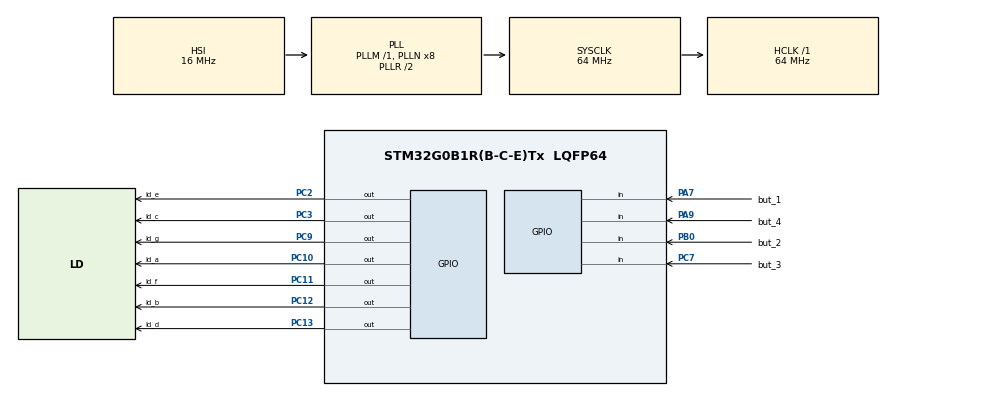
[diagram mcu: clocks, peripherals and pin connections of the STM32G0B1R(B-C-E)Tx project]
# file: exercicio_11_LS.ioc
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Mcu.Family=STM32G0
Mcu.Name=STM32G0B1R(B-C-E)Tx
Mcu.Package=LQFP64
PA13.Mode=Serial_Wire
PA13.Signal=SYS_SWDIO
PA14-BOOT0.Mode=Serial_Wire
PA14-BOOT0.Signal=SYS_SWCLK
PA7.GPIO_Label=but_1
PA7.GPIO_PuPd=GPIO_PULLUP
PA7.Signal=GPIO_Input
PA9.GPIO_Label=but_4
PA9.GPIO_PuPd=GPIO_PULLUP
PA9.Signal=GPIO_Input
PB0.GPIO_Label=but_2
PB0.GPIO_PuPd=GPIO_PULLUP
PB0.Signal=GPIO_Input
PC10.GPIO_Label=ld_a
PC10.PinState=GPIO_PIN_SET
PC10.Signal=GPIO_Output
PC11.GPIO_Label=ld_f
PC11.PinState=GPIO_PIN_SET
PC11.Signal=GPIO_Output
PC12.GPIO_Label=ld_b
PC12.PinState=GPIO_PIN_SET
PC12.Signal=GPIO_Output
PC13.GPIO_Label=ld_d
PC13.PinState=GPIO_PIN_SET
PC13.Signal=GPIO_Output
PC2.GPIO_Label=ld_e
PC2.PinState=GPIO_PIN_SET
PC2.Signal=GPIO_Output
PC3.GPIO_Label=ld_c
PC3.PinState=GPIO_PIN_SET
PC3.Signal=GPIO_Output
PC7.GPIO_Label=but_3
PC7.GPIO_PuPd=GPIO_PULLUP
PC7.Signal=GPIO_Input
PC9.GPIO_Label=ld_g
PC9.PinState=GPIO_PIN_SET
PC9.Signal=GPIO_Output
ProjectManager.HeapSize=0x200
ProjectManager.StackSize=0x400
ProjectManager.TargetToolchain=STM32CubeIDE
RCC.ADCFreq_Value=64000000
RCC.AHBFreq_Value=64000000
RCC.CortexFreq_Value=64000000
RCC.EXTERNAL_CLOCK_VALUE=48000
RCC.HCLKFreq_Value=64000000
RCC.HSE_VALUE=8000000
RCC.HSI48_VALUE=48000000
RCC.HSI_VALUE=16000000
RCC.LSE_VALUE=32768
RCC.SYSCLKFreq_VALUE=64000000
RCC.SYSCLKSource=RCC_SYSCLKSOURCE_PLLCLK
RCC.USBFreq_Value=48000000
RCC.VCOOutputFreq_Value=128000000
VP_SYS_VS_DBSignals.Mode=DisableDeadBatterySignals
board=custom

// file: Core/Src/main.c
/* USER CODE BEGIN Header */
/**
  ******************************************************************************
  * @file           : main.c
  * @brief          : Main program body
  ******************************************************************************
  * @attention
  *
  * Copyright (c) 2022 STMicroelectronics.
  * All rights reserved.
  *
  * This software is licensed under terms that can be found in the LICENSE file
  * in the root directory of this software component.
  * If no LICENSE file comes with this software, it is provided AS-IS.
  *
  ******************************************************************************
  */
/* USER CODE END Header */
#include "main.h"

/* USER CODE BEGIN PV */

uint8_t b1, b2, b3, b4;

uint16_t numero;

/* USER CODE END PV */

void SystemClock_Config(void);
static void MX_GPIO_Init(void);

int main(void)
{

  /* MCU Configuration--------------------------------------------------------*/

  /* Reset of all peripherals, Initializes the Flash interface and the Systick. */
  HAL_Init();

  /* Configure the system clock */
  SystemClock_Config();

  /* Initialize all configured peripherals */
  MX_GPIO_Init();

  /* Infinite loop */
  /* USER CODE BEGIN WHILE */

  numero = 12;
  while (1)
  {
	  b1 = HAL_GPIO_ReadPin(but_1_GPIO_Port, but_1_Pin);
	  b2 = HAL_GPIO_ReadPin(but_2_GPIO_Port, but_2_Pin);
	  b3 = HAL_GPIO_ReadPin(but_3_GPIO_Port, but_3_Pin);
	  b4 = HAL_GPIO_ReadPin(but_4_GPIO_Port, but_4_Pin);

	  numero = b4 + b3*2 + b2*4 + b1*8;

/*	  switch (numero){

  	  case 0:
  		  HAL_GPIO_WritePin(ld_a_GPIO_Port, ld_a_Pin, 0);
  		  HAL_GPIO_WritePin(ld_b_GPIO_Port, ld_b_Pin, 0);
  		  HAL_GPIO_WritePin(ld_c_GPIO_Port, ld_c_Pin, 0);
  		  HAL_GPIO_WritePin(ld_d_GPIO_Port, ld_d_Pin, 0);
  		  HAL_GPIO_WritePin(ld_e_GPIO_Port, ld_e_Pin, 0);
  		  HAL_GPIO_WritePin(ld_f_GPIO_Port, ld_f_Pin, 0);
  		  HAL_GPIO_WritePin(ld_g_GPIO_Port, ld_g_Pin, 1);

  		  break;

	  	  case 1:
	  		  HAL_GPIO_WritePin(ld_a_GPIO_Port, ld_a_Pin, 1);
	  		  HAL_GPIO_WritePin(ld_b_GPIO_Port, ld_b_Pin, 0);
	  		  HAL_GPIO_WritePin(ld_c_GPIO_Port, ld_c_Pin, 0);
	  		  HAL_GPIO_WritePin(ld_d_GPIO_Port, ld_d_Pin, 1);
	  		  HAL_GPIO_WritePin(ld_e_GPIO_Port, ld_e_Pin, 1);
	  		  HAL_GPIO_WritePin(ld_f_GPIO_Port, ld_f_Pin, 1);
	  		  HAL_GPIO_WritePin(ld_g_GPIO_Port, ld_g_Pin, 1);

	  		  break;

	  	  case 2:

	  		  HAL_GPIO_WritePin(ld_a_GPIO_Port, ld_a_Pin, 0);
	  		  HAL_GPIO_WritePin(ld_b_GPIO_Port, ld_b_Pin, 0);
	  		  HAL_GPIO_WritePin(ld_c_GPIO_Port, ld_c_Pin, 1);
	  		  HAL_GPIO_WritePin(ld_d_GPIO_Port, ld_d_Pin, 0);
	  		  HAL_GPIO_WritePin(ld_e_GPIO_Port, ld_e_Pin, 0);
	  		  HAL_GPIO_WritePin(ld_f_GPIO_Port, ld_f_Pin, 1);
	  		  HAL_GPIO_WritePin(ld_g_GPIO_Port, ld_g_Pin, 0);

	  		  break;

	  	  case 3:

	  		  HAL_GPIO_WritePin(ld_a_GPIO_Port, ld_a_Pin, 0);
	  		  HAL_GPIO_WritePin(ld_b_GPIO_Port, ld_b_Pin, 0);
	  		  HAL_GPIO_WritePin(ld_c_GPIO_Port, ld_c_Pin, 0);
	  		  HAL_GPIO_WritePin(ld_d_GPIO_Port, ld_d_Pin, 0);
	  		  HAL_GPIO_WritePin(ld_e_GPIO_Port, ld_e_Pin, 1);
	  		  HAL_GPIO_WritePin(ld_f_GPIO_Port, ld_f_Pin, 1);
	  		  HAL_GPIO_WritePin(ld_g_GPIO_Port, ld_g_Pin, 0);

	  		  break;

	  	  case 4:
	  		  HAL_GPIO_WritePin(ld_a_GPIO_Port, ld_a_Pin, 1);
	  		  HAL_GPIO_WritePin(ld_b_GPIO_Port, ld_b_Pin, 0);
	  		  HAL_GPIO_WritePin(ld_c_GPIO_Port, ld_c_Pin, 0);
	  		  HAL_GPIO_WritePin(ld_d_GPIO_Port, ld_d_Pin, 1);
	  		  HAL_GPIO_WritePin(ld_e_GPIO_Port, ld_e_Pin, 1);
	  		  HAL_GPIO_WritePin(ld_g_GPIO_Port, ld_g_Pin, 0);
	  		  HAL_GPIO_WritePin(ld_f_GPIO_Port, ld_f_Pin, 0);

	  		  break;

	  	  case 5:

	  		  HAL_GPIO_WritePin(ld_a_GPIO_Port, ld_a_Pin, 0);
	  		  HAL_GPIO_WritePin(ld_b_GPIO_Port, ld_b_Pin, 1);
	  		  HAL_GPIO_WritePin(ld_c_GPIO_Port, ld_c_Pin, 0);
	  		  HAL_GPIO_WritePin(ld_d_GPIO_Port, ld_d_Pin, 0);
	  		  HAL_GPIO_WritePin(ld_e_GPIO_Port, ld_e_Pin, 1);
	  		  HAL_GPIO_WritePin(ld_f_GPIO_Port, ld_f_Pin, 0);
	  		  HAL_GPIO_WritePin(ld_g_GPIO_Port, ld_g_Pin, 0);

	  		  break;

	  	  case 6:

	  		  HAL_GPIO_WritePin(ld_b_GPIO_Port, ld_b_Pin, 1);
	  		  HAL_GPIO_WritePin(ld_a_GPIO_Port, ld_a_Pin, 0);
	  		  HAL_GPIO_WritePin(ld_f_GPIO_Port, ld_f_Pin, 0);
	  		  HAL_GPIO_WritePin(ld_e_GPIO_Port, ld_e_Pin, 0);
	  		  HAL_GPIO_WritePin(ld_d_GPIO_Port, ld_d_Pin, 0);
	  		  HAL_GPIO_WritePin(ld_g_GPIO_Port, ld_g_Pin, 0);
	  		  HAL_GPIO_WritePin(ld_c_GPIO_Port, ld_c_Pin, 0);

	  		  break;

	  	  case 7:
	  		  HAL_GPIO_WritePin(ld_a_GPIO_Port, ld_a_Pin, 0);
	  		  HAL_GPIO_WritePin(ld_b_GPIO_Port, ld_b_Pin, 0);
	  		  HAL_GPIO_WritePin(ld_c_GPIO_Port, ld_c_Pin, 0);
	  		  HAL_GPIO_WritePin(ld_d_GPIO_Port, ld_d_Pin, 1);
	  		  HAL_GPIO_WritePin(ld_e_GPIO_Port, ld_e_Pin, 1);
	  		  HAL_GPIO_WritePin(ld_f_GPIO_Port, ld_f_Pin, 1);
	  		  HAL_GPIO_WritePin(ld_g_GPIO_Port, ld_g_Pin, 1);

	  		  break;

	  	  case 8:
	  		  HAL_GPIO_WritePin(ld_a_GPIO_Port, ld_a_Pin, 0);
	  		  HAL_GPIO_WritePin(ld_b_GPIO_Port, ld_b_Pin, 0);
	  		  HAL_GPIO_WritePin(ld_c_GPIO_Port, ld_c_Pin, 0);
	  		  HAL_GPIO_WritePin(ld_d_GPIO_Port, ld_d_Pin, 0);
	  		  HAL_GPIO_WritePin(ld_e_GPIO_Port, ld_e_Pin, 0);
	  		  HAL_GPIO_WritePin(ld_f_GPIO_Port, ld_f_Pin, 0);
	  		  HAL_GPIO_WritePin(ld_g_GPIO_Port, ld_g_Pin, 0);

	  		  break;

	  	  case 9:
	  		  HAL_GPIO_WritePin(ld_a_GPIO_Port, ld_a_Pin, 0);
	  		  HAL_GPIO_WritePin(ld_b_GPIO_Port, ld_b_Pin, 0);
	  		  HAL_GPIO_WritePin(ld_c_GPIO_Port, ld_c_Pin, 0);
	  		  HAL_GPIO_WritePin(ld_d_GPIO_Port, ld_d_Pin, 0);
	  		  HAL_GPIO_WritePin(ld_e_GPIO_Port, ld_e_Pin, 1);
	  		  HAL_GPIO_WritePin(ld_f_GPIO_Port, ld_f_Pin, 0);
	  		  HAL_GPIO_WritePin(ld_g_GPIO_Port, ld_g_Pin, 0);

	  		  break;

	  	  case 10:
	  		  HAL_GPIO_WritePin(ld_a_GPIO_Port, ld_a_Pin, 0);
	  		  HAL_GPIO_WritePin(ld_b_GPIO_Port, ld_b_Pin, 0);
	  		  HAL_GPIO_WritePin(ld_c_GPIO_Port, ld_c_Pin, 0);
	  		  HAL_GPIO_WritePin(ld_d_GPIO_Port, ld_d_Pin, 1);
	  		  HAL_GPIO_WritePin(ld_e_GPIO_Port, ld_e_Pin, 0);
	  		  HAL_GPIO_WritePin(ld_f_GPIO_Port, ld_f_Pin, 0);
	  		  HAL_GPIO_WritePin(ld_g_GPIO_Port, ld_g_Pin, 0);

	  		  break;

	  	  case 11:
	  		  HAL_GPIO_WritePin(ld_a_GPIO_Port, ld_a_Pin, 0);
	  		  HAL_GPIO_WritePin(ld_b_GPIO_Port, ld_b_Pin, 0);
	  		  HAL_GPIO_WritePin(ld_c_GPIO_Port, ld_c_Pin, 0);
	  		  HAL_GPIO_WritePin(ld_d_GPIO_Port, ld_d_Pin, 0);
	  		  HAL_GPIO_WritePin(ld_e_GPIO_Port, ld_e_Pin, 0);
	  		  HAL_GPIO_WritePin(ld_f_GPIO_Port, ld_f_Pin, 0);
	  		  HAL_GPIO_WritePin(ld_g_GPIO_Port, ld_g_Pin, 0);

	  		  break;

	  	  case 12:
	  		  HAL_GPIO_WritePin(ld_a_GPIO_Port, ld_a_Pin, 0);
	  		  HAL_GPIO_WritePin(ld_b_GPIO_Port, ld_b_Pin, 1);
	  		  HAL_GPIO_WritePin(ld_c_GPIO_Port, ld_c_Pin, 1);
	  		  HAL_GPIO_WritePin(ld_d_GPIO_Port, ld_d_Pin, 0);
	  		  HAL_GPIO_WritePin(ld_e_GPIO_Port, ld_e_Pin, 0);
	  		  HAL_GPIO_WritePin(ld_f_GPIO_Port, ld_f_Pin, 0);
	  		  HAL_GPIO_WritePin(ld_g_GPIO_Port, ld_g_Pin, 1);

	  		  break;

	  	  case 13:
	  		  HAL_GPIO_WritePin(ld_a_GPIO_Port, ld_a_Pin, 0);
	  		  HAL_GPIO_WritePin(ld_b_GPIO_Port, ld_b_Pin, 0);
	  		  HAL_GPIO_WritePin(ld_c_GPIO_Port, ld_c_Pin, 0);
	  		  HAL_GPIO_WritePin(ld_d_GPIO_Port, ld_d_Pin, 0);
	  		  HAL_GPIO_WritePin(ld_e_GPIO_Port, ld_e_Pin, 0);
	  		  HAL_GPIO_WritePin(ld_f_GPIO_Port, ld_f_Pin, 0);
	  		  HAL_GPIO_WritePin(ld_g_GPIO_Port, ld_g_Pin, 1);

	  		  break;

	  	  case 14:
	  		  HAL_GPIO_WritePin(ld_a_GPIO_Port, ld_a_Pin, 0);
	  		  HAL_GPIO_WritePin(ld_b_GPIO_Port, ld_b_Pin, 1);
	  		  HAL_GPIO_WritePin(ld_c_GPIO_Port, ld_c_Pin, 1);
	  		  HAL_GPIO_WritePin(ld_d_GPIO_Port, ld_d_Pin, 0);
	  		  HAL_GPIO_WritePin(ld_e_GPIO_Port, ld_e_Pin, 0);
	  		  HAL_GPIO_WritePin(ld_f_GPIO_Port, ld_f_Pin, 0);
	  		  HAL_GPIO_WritePin(ld_g_GPIO_Port, ld_g_Pin, 0);

	  		  break;

	  	  case 15:
	  		  HAL_GPIO_WritePin(ld_a_GPIO_Port, ld_a_Pin, 0);
	  		  HAL_GPIO_WritePin(ld_b_GPIO_Port, ld_b_Pin, 1);
	  		  HAL_GPIO_WritePin(ld_c_GPIO_Port, ld_c_Pin, 1);
	  		  HAL_GPIO_WritePin(ld_d_GPIO_Port, ld_d_Pin, 1);
	  		  HAL_GPIO_WritePin(ld_e_GPIO_Port, ld_e_Pin, 0);
	  		  HAL_GPIO_WritePin(ld_f_GPIO_Port, ld_f_Pin, 0);
	  		  HAL_GPIO_WritePin(ld_g_GPIO_Port, ld_g_Pin, 0);

	  		  break;

	  }

	*/

    /* USER CODE END WHILE */

  }
}

void SystemClock_Config(void)
{
  RCC_OscInitTypeDef RCC_OscInitStruct = {0};
  RCC_ClkInitTypeDef RCC_ClkInitStruct = {0};

  /** Configure the main internal regulator output voltage
  */
  HAL_PWREx_ControlVoltageScaling(PWR_REGULATOR_VOLTAGE_SCALE1);
  /** Initializes the RCC Oscillators according to the specified parameters
  * in the RCC_OscInitTypeDef structure.
  */
  RCC_OscInitStruct.OscillatorType = RCC_OSCILLATORTYPE_HSI;
  RCC_OscInitStruct.HSIState = RCC_HSI_ON;
  RCC_OscInitStruct.HSIDiv = RCC_HSI_DIV1;
  RCC_OscInitStruct.HSICalibrationValue = RCC_HSICALIBRATION_DEFAULT;
  RCC_OscInitStruct.PLL.PLLState = RCC_PLL_ON;
  RCC_OscInitStruct.PLL.PLLSource = RCC_PLLSOURCE_HSI;
  RCC_OscInitStruct.PLL.PLLM = RCC_PLLM_DIV1;
  RCC_OscInitStruct.PLL.PLLN = 8;
  RCC_OscInitStruct.PLL.PLLP = RCC_PLLP_DIV2;
  RCC_OscInitStruct.PLL.PLLQ = RCC_PLLQ_DIV2;
  RCC_OscInitStruct.PLL.PLLR = RCC_PLLR_DIV2;
  if (HAL_RCC_OscConfig(&RCC_OscInitStruct) != HAL_OK)
  {
    Error_Handler();
  }
  /** Initializes the CPU, AHB and APB buses clocks
  */
  RCC_ClkInitStruct.ClockType = RCC_CLOCKTYPE_HCLK|RCC_CLOCKTYPE_SYSCLK
                              |RCC_CLOCKTYPE_PCLK1;
  RCC_ClkInitStruct.SYSCLKSource = RCC_SYSCLKSOURCE_PLLCLK;
  RCC_ClkInitStruct.AHBCLKDivider = RCC_SYSCLK_DIV1;
  RCC_ClkInitStruct.APB1CLKDivider = RCC_HCLK_DIV1;

  if (HAL_RCC_ClockConfig(&RCC_ClkInitStruct, FLASH_LATENCY_2) != HAL_OK)
  {
    Error_Handler();
  }
}

static void MX_GPIO_Init(void)
{
  GPIO_InitTypeDef GPIO_InitStruct = {0};

  /* GPIO Ports Clock Enable */
  __HAL_RCC_GPIOC_CLK_ENABLE();
  __HAL_RCC_GPIOA_CLK_ENABLE();
  __HAL_RCC_GPIOB_CLK_ENABLE();

  /*Configure GPIO pin Output Level */
  HAL_GPIO_WritePin(GPIOC, ld_f_Pin|ld_b_Pin|ld_d_Pin|ld_e_Pin
                          |ld_c_Pin|ld_g_Pin|ld_a_Pin, GPIO_PIN_SET);

  /*Configure GPIO pins : ld_f_Pin ld_b_Pin ld_d_Pin ld_e_Pin
                           ld_c_Pin ld_g_Pin ld_a_Pin */
  GPIO_InitStruct.Pin = ld_f_Pin|ld_b_Pin|ld_d_Pin|ld_e_Pin
                          |ld_c_Pin|ld_g_Pin|ld_a_Pin;
  GPIO_InitStruct.Mode = GPIO_MODE_OUTPUT_PP;
  GPIO_InitStruct.Pull = GPIO_NOPULL;
  GPIO_InitStruct.Speed = GPIO_SPEED_FREQ_LOW;
  HAL_GPIO_Init(GPIOC, &GPIO_InitStruct);

  /*Configure GPIO pins : but_1_Pin but_4_Pin */
  GPIO_InitStruct.Pin = but_1_Pin|but_4_Pin;
  GPIO_InitStruct.Mode = GPIO_MODE_INPUT;
  GPIO_InitStruct.Pull = GPIO_PULLUP;
  HAL_GPIO_Init(GPIOA, &GPIO_InitStruct);

  /*Configure GPIO pin : but_2_Pin */
  GPIO_InitStruct.Pin = but_2_Pin;
  GPIO_InitStruct.Mode = GPIO_MODE_INPUT;
  GPIO_InitStruct.Pull = GPIO_PULLUP;
  HAL_GPIO_Init(but_2_GPIO_Port, &GPIO_InitStruct);

  /*Configure GPIO pin : but_3_Pin */
  GPIO_InitStruct.Pin = but_3_Pin;
  GPIO_InitStruct.Mode = GPIO_MODE_INPUT;
  GPIO_InitStruct.Pull = GPIO_PULLUP;
  HAL_GPIO_Init(but_3_GPIO_Port, &GPIO_InitStruct);

}

void Error_Handler(void)
{
  __disable_irq();
  while (1)
  {
  }
}
